# MB9BF52xK register map
File version: 1.7
Registers are 8-bit, read-write, reset 0x0 unless marked. A register's access mark holds for its fields unless they carry their own. Offsets are from the block's base; [hi:lo] are bit positions; {n}, {i} and the like mark numbered series; 'fields as' and 'values as' point back to an identical list.

## EXTI — External Interrupt and NMI Control
Base 0x40030000
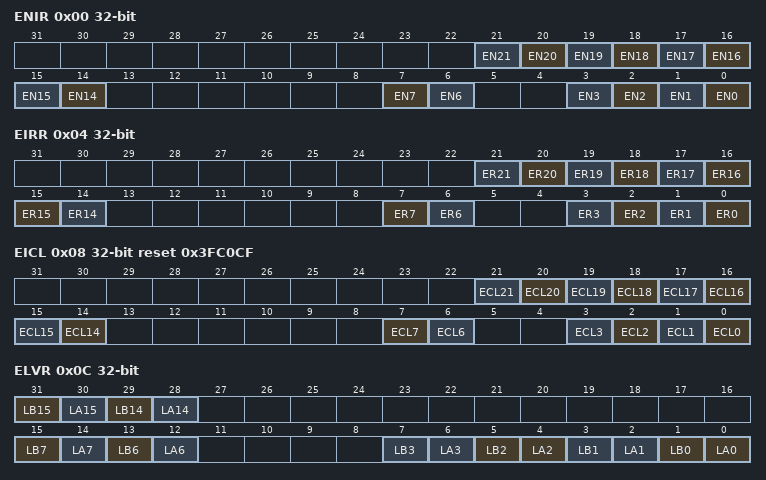
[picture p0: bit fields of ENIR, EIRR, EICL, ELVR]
0x00 ENIR 32-bit — Enable Interrupt Request Register
  [n] EN{n} (n=14..21) — Bit{n} of ENIR
  [7] EN7 — Bit7 of ENIR
  [6] EN6 — Bit6 of ENIR
  [n] EN{n} (n=0..3) — Bit{n} of ENIR
0x04 EIRR 32-bit ro reset not defined — External Interrupt Request Register
  [n] ER{n} rw (n=16..21) — Bit{n} of EIRR
  [15] ER15 — Bit15 of EIRR
  [14] ER14 — Bit14 of EIRR
  [7] ER7 — Bit7 of EIRR
  [6] ER6 — Bit6 of EIRR
  [n] ER{n} (n=0..3) — Bit{n} of EIRR
0x08 EICL 32-bit reset 0x3FC0CF — External Interrupt Clear Register
  [n] ECL{n} (n=14..21) — Bit{n} of EICL
  [7] ECL7 — Bit7 of EICL
  [6] ECL6 — Bit6 of EICL
  [n] ECL{n} (n=0..3) — Bit{n} of EICL
0x0C ELVR 32-bit — External Interrupt Level Register
  [31] LB15 — Bit31 of ELVR
  [30] LA15 — Bit30 of ELVR
  [29] LB14 — Bit29 of ELVR
  [28] LA14 — Bit28 of ELVR
  [15] LB7 — Bit15 of ELVR
  [14] LA7 — Bit14 of ELVR
  [13] LB6 — Bit13 of ELVR
  [12] LA6 — Bit12 of ELVR
  [2n+1] LB{n} (n=0..3) — Bit{2n+1} of ELVR
  [2n] LA{n} (n=0..3) — Bit{2n} of ELVR
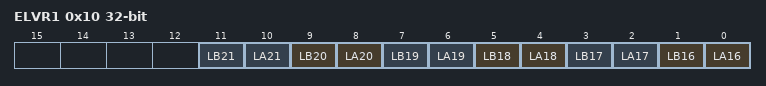
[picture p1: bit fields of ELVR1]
0x10 ELVR1 32-bit — External Interrupt Level Register 1
  [2n-31] LB{n} (n=16..21) — Bit{2n-31} of ELVR1
  [2n-32] LA{n} (n=16..21) — Bit{2n-32} of ELVR1
0x14 NMIRR ro — Non Maskable Interrupt Request Register
  [0] NR — NMI interrupt request detection bit
0x18 NMICL reset 0x1 — Non Maskable Interrupt Clear Register
  [0] NCL — NMI interrupt cause clear bit

## LVD — Low-voltage Detection
Base 0x40035000
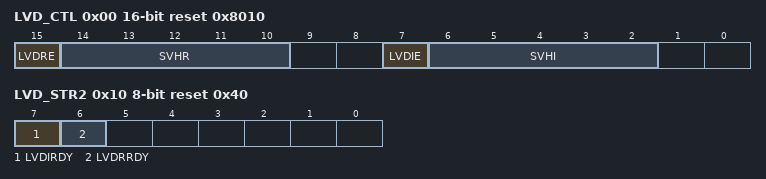
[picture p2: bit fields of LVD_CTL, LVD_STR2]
0x00 LVD_CTL 16-bit reset 0x8010 — Low-voltage Detection Voltage Control Register
  [15] LVDRE — Low-voltage detection reset operation enable bit
  [14:10] SVHR — Low-voltage detection reset voltage setting bits
  [7] LVDIE — Low-voltage detection interrupt enable bit
  [6:2] SVHI — Low-voltage detection interrupt voltage setting bits
0x04 LVD_STR ro — Low-voltage Detection Interrupt Register
  [7] LVDIR — Low-voltage detection interrupt bit
0x08 LVD_CLR reset 0x80 — Low-voltage Detection Interrupt Clear Register
  [7] LVDCL — Low-voltage detection interrupt clear bit
0x0C LVD_RLR 32-bit reset 0x1 — Low-voltage Detection Voltage Protection Register
  [31:0] LVDLCK — Low-voltage Detection Voltage Control Register protection bits
0x10 LVD_STR2 ro reset 0x40 — Low-voltage Detection Circuit Status Register
  [7] LVDIRDY — Low-voltage detection interrupt status flag
  [6] LVDRRDY — Low-voltage detection reset status flag

## DS — Low Power Consumption Mode
Base 0x40035100
0x00 REG_CTL reset 0x4 — Sub Oscillation Circuit Power Supply Control Register
  [2:1] ISUBSEL — Sub oscillation circuit current setting bits
0x04 RCK_CTL reset 0x1 — Sub Clock Control Register
  [0] RTCCKE — RTC clock control bit
0x700 PMD_CTL — RTC Mode Control Register
  [0] RTCE — RTC mode control bit
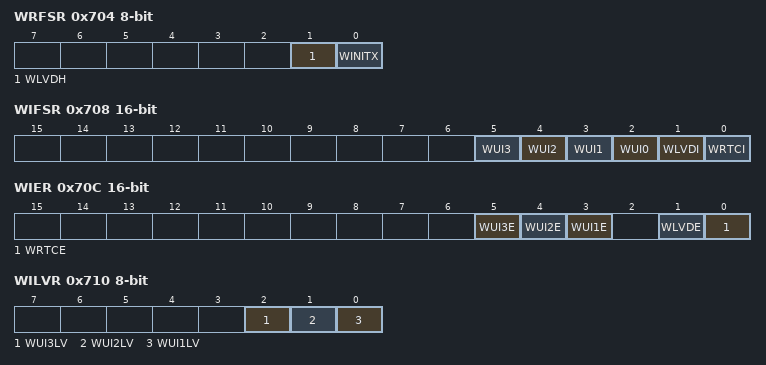
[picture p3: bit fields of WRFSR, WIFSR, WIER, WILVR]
0x704 WRFSR — Deep Standby Return Cause Register 1
  [1] WLVDH — Low-voltage detection reset return bit
  [0] WINITX — INITX pin input reset return bit
0x708 WIFSR 16-bit ro — Deep Standby Return Cause Register 2
  [n+2] WUI{n} (n=0..3) — WKUP pin input return bit {n}
  [1] WLVDI — LVD interrupt return bit
  [0] WRTCI — RTC interrupt return bit
0x70C WIER 16-bit — Deep Standby Return Enable Register
  [5] WUI3E — WKUP pin input return enable bit 3
  [4] WUI2E — WKUP pin input return enable bit 2
  [3] WUI1E — WKUP pin input return enable bit 1
  [1] WLVDE — LVD interrupt return enable bit
  [0] WRTCE — RTC interrupt return enable bit
0x710 WILVR — WKUP Pin Input Level Register
  [2] WUI3LV — WKUP pin input level select bit 3
  [1] WUI2LV — WKUP pin input level select bit 2
  [0] WUI1LV — WKUP pin input level select bit 1
0x714 DSRAMR — Deep Standby RAM Retention Register
  [1:0] SRAMR — On-chip SRAM retention control bits
{0x7FF+i} BUR{i:02} (i=1..16) — Backup Registers from {i}

## CRC — CRC Registers
Base 0x40039000
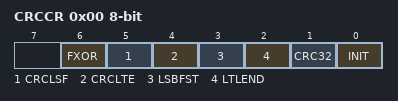
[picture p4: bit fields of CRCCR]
0x00 CRCCR — CRC Control Register
  [6] FXOR — Initialization bit
  [5] CRCLSF — Final XOR control bit
  [4] CRCLTE — CRC result bit-order setting bit
  [3] LSBFST — CRC result byte-order setting bit
  [2] LTLEND — Bit-order setting bit
  [1] CRC32 — Byte-order setting bit
  [0] INIT — CRC mode selection bit
0x04 CRCINIT 32-bit reset 0xFFFFFFFF — Initial Value Register
  [31:0] D — Initial value
0x08 CRCIN 32-bit — Input Data Register
  [31:0] D — Input data
0x0C CRCR 32-bit ro reset 0xFFFFFFFF — CRC Register
  [31:0] D — CRC Data

## USBCLK — USB Clock
Base 0x40036000
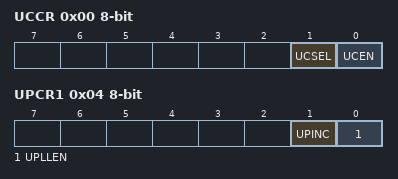
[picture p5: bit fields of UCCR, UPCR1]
0x00 UCCR — USB Clock Control Register
  [1] UCSEL — USB clock selection bit
  [0] UCEN — USB clock output enable bit
0x04 UPCR1 — USB-PLL Control Register 1
  [1] UPINC — USB-PLL input clock selection bit
  [0] UPLLEN — USB-PLL oscillation enable bit
0x08 UPCR2 — USB-PLL Control Register 2
  [2:0] UPOWT — USB-PLL oscillation stabilization wait time setting bit
0x0C UPCR3 — USB-PLL Control Register 3
  [4:0] UPLLK — Frequency division ratio (K) setting bit of the USB-PLL clock
0x10 UPCR4 reset 0x17 — USB-PLL Control Register 4
  [4:0] UPLLN — Frequency division ratio (N) setting bit of the USB-PLL clock
0x14 UP_STR ro — USB-PLL Status Register
  [0] UPRDY — USB-PLL oscillation stabilization bit
0x18 UPINT_ENR — USB-PLL Interrupt Source Enable Register
  [0] UPCSE — USB-PLL oscillation stabilization wait complete interrupt enable bit
0x1C UPINT_CLR wo — USB-PLL Interrupt Source Clear Register
  [0] UPCSC — USB-PLL oscillation stabilization interrupt source clear bit
0x20 UPINT_STR ro — USB-PLL Interrupt Source Status Register
  [0] UPCSI — USB-PLL interrupt source status bit
0x24 UPCR5 reset 0x4 — USB-PLL Control Register 5
  [3:0] UPLLM — Frequency division ratio (M) setting bit of the USB-PLL clock
0x30 USBEN — USB Enable Register
  [0] USBEN — USB enable bit

## DMAC — DMAC Registers
Base 0x40060000
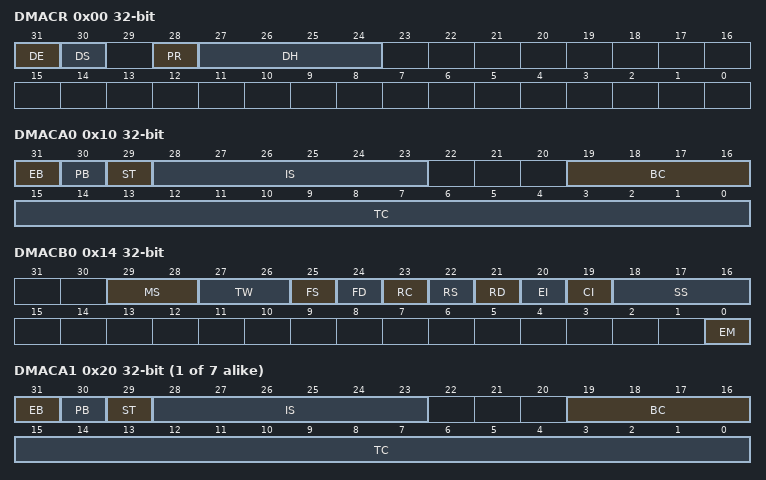
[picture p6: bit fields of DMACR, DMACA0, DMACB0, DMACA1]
0x00 DMACR 32-bit — Entire DMAC Configuration Register
  [31] DE — DMA Enable (all-channel operation enable bit)
  [30] DS — DMA Stop
  [28] PR — Priority Rotation
  [27:24] DH — DMA Halt (All-channel pause bit)
0x10 DMACA0 32-bit — Configuration A Register
  [31] EB — Enable bit (individual-channel operation enable bit)
  [30] PB — Pause bit (individual-channel pause bit)
  [29] ST — Software Trigger
  [28:23] IS — Input Select
  [19:16] BC — Block Count
  [15:0] TC — Transfer Count
0x14 DMACB0 32-bit — Configuration B Register
  [29:28] MS — Mode Select
  [27:26] TW — Transfer Width
  [25] FS — Fixed Source
  [24] FD — Fixed Destination
  [23] RC — Reload Count (BC/TC reload)
  [22] RS — Reload Source
  [21] RD — Reload Destination
  [20] EI — Error Interrupt (unsuccessful transfer completion interrupt enable)
  [19] CI — Completion Interrupt (successful transfer completion interrupt enable)
  [18:16] SS — Stop Status (stop status notification)
  [0] EM — Enable bit Mask (EB bit clear mask)
0x18 DMACSA0 32-bit — Transfer Source Address Register
0x1C DMACDA0 32-bit — Transfer Destination Address Register
{0x10+0x10*i} DMACA{i} 32-bit (i=1..7) — Configuration A Register {i}
  fields as DMACA0
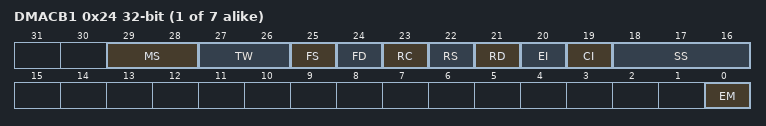
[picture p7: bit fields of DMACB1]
{0x14+0x10*i} DMACB{i} 32-bit (i=1..7) — Configuration B Register {i}
  fields as DMACB0
{0x18+0x10*i} DMACSA{i} 32-bit (i=1..7) — Transfer Source Address Register {i}
{0x1C+0x10*i} DMACDA{i} 32-bit (i=1..7) — Transfer Destination Address Register {i}

## CANPRES — CAN Prescaler Register
Base 0x40037000
0x00 CANPRE reset 0xB (reset mask 0xF) — CAN Prescaler Register

## Notices in the file
Licence Terms
FUJITSU SEMICONDUCTOR LIMITED (gLICENSORh) hereby grants and
you (gLICENSEEh) hereby accept a non transferable, non-exclusive
licence to use and copy the deliverables (gDeliverablesh) solely for
the purpose of; (i) developing LICENSEEfs development tools and
distributing such development tools to third parties; (ii) generating
derivative representations of the Deliverables to develop and debug
software for LICENSORfs targeted devices or device series identified
within the Deliverables, (together the gPurposeh) under the following
terms and conditions:
1. Ownership.
The Deliverables are the property of LICENSOR. LICENSEE acquires no
right, title or interest in the Deliverables other than the licence
rights granted herein.
2. Use.
LICENSEE shall only be permitted to use the Deliverables for the
Purpose. LICENSEE shall not reverse engineer, decompile or
disassemble the Deliverables, in whole or in part.
3. Copies.
All copies of the Deliverables must bear the same notice(s) contained
on the original copies of the Deliverables.
4. No Warranty.
THE DELIVERABLES ARE PROVIDED gAS ISh AND ANY EXPRESS, IMPLIED OR
STATUTORY WARRANTIES, INCLUDING, BUT NOT LIMITED TO, THE IMPLIED
WARRANTIES OF MERCHANTABILITY, SATISFACTORY QUALITY AND FITNESS FOR
A PARTICULAR PURPOSE ARE DISCLAIMED.
IN NO EVENT SHALL LICENSOR BE LIABLE FOR ANY DIRECT, INDIRECT,
INCIDENTAL, SPECIAL, EXEMPLARY, OR CONSEQUENTIAL DAMAGES HOWEVER CAUSED
AND ON ANY THEORY OF LIABILITY, WHETHER IN CONTRACT, STRICT LIABILITY,
OR TORT (INCLUDING NEGLIGENCE OR OTHERWISE) ARISING IN ANY WAY OUT OF
THE USE OF THE DELIVERABLES, EVEN IF ADVISED OF THE POSSIBILITY OF SUCH
DAMAGE.
LICENSEE EXPRESSLY ASSUMES ALL LIABILITIES AND RISKS, FOR USE OR
OPERATION OF THE DELIVERABLES.
5.In the event that LICENSEE receives early access to the Deliverables,
LICENSEE acknowledges and agrees that;
(a) notwithstanding the licence grants above, LICENSEE shall only be
permitted to use the Deliverables solely internally for evaluation and
providing feedback to LICENSOR;
(b) except with respect to the limited licence grants in 5(a), LICENSEE
shall be subject to all of the terms and conditions set out above; and
(c) the Deliverables are confidential information and LICENSEE shall
maintain in confidence the Deliverables and apply security measures no
less stringent than the measures that LICENSEE applies to its own like
information, but not less than a reasonable degree of care, to prevent
unauthorised disclosure and use of the Deliverables.
